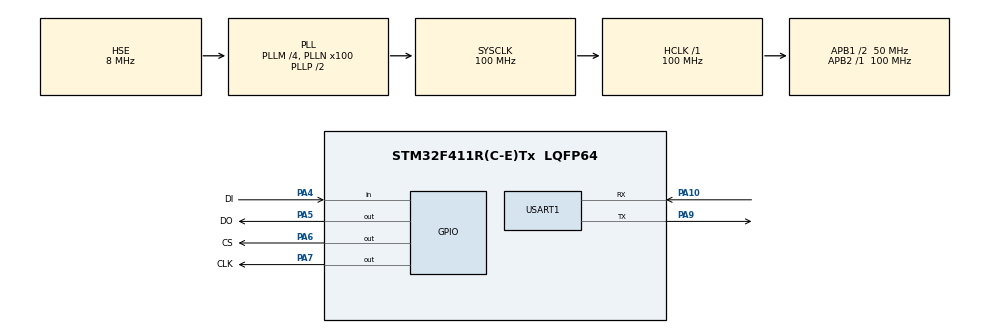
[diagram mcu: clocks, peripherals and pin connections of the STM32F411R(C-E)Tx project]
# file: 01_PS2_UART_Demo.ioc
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Mcu.Family=STM32F4
Mcu.Name=STM32F411R(C-E)Tx
Mcu.Package=LQFP64
NVIC.PriorityGroup=NVIC_PRIORITYGROUP_4
PA10.Mode=Asynchronous
PA10.Signal=USART1_RX
PA13.Mode=Serial_Wire
PA13.Signal=SYS_JTMS-SWDIO
PA14.Mode=Serial_Wire
PA14.Signal=SYS_JTCK-SWCLK
PA4.GPIO_Label=DI
PA4.GPIO_PuPd=GPIO_PULLUP
PA4.Signal=GPIO_Input
PA5.GPIO_Label=DO
PA5.GPIO_Speed=GPIO_SPEED_FREQ_HIGH
PA5.PinState=GPIO_PIN_SET
PA5.Signal=GPIO_Output
PA6.GPIO_Label=CS
PA6.GPIO_Speed=GPIO_SPEED_FREQ_HIGH
PA6.PinState=GPIO_PIN_SET
PA6.Signal=GPIO_Output
PA7.GPIO_Label=CLK
PA7.GPIO_Speed=GPIO_SPEED_FREQ_HIGH
PA7.PinState=GPIO_PIN_SET
PA7.Signal=GPIO_Output
PA9.Mode=Asynchronous
PA9.Signal=USART1_TX
PH0\ -\ OSC_IN.Mode=HSE-External-Oscillator
PH0\ -\ OSC_IN.Signal=RCC_OSC_IN
PH1\ -\ OSC_OUT.Mode=HSE-External-Oscillator
PH1\ -\ OSC_OUT.Signal=RCC_OSC_OUT
ProjectManager.HeapSize=0x200
ProjectManager.StackSize=0x400
ProjectManager.TargetToolchain=MDK-ARM V5
RCC.48MHZClocksFreq_Value=50000000
RCC.AHBFreq_Value=100000000
RCC.APB1CLKDivider=RCC_HCLK_DIV2
RCC.APB1Freq_Value=50000000
RCC.APB1TimFreq_Value=100000000
RCC.APB2Freq_Value=100000000
RCC.APB2TimFreq_Value=100000000
RCC.CortexFreq_Value=100000000
RCC.HCLKFreq_Value=100000000
RCC.HSE_VALUE=8000000
RCC.HSI_VALUE=16000000
RCC.LSE_VALUE=32768
RCC.PLLM=4
RCC.PLLN=100
RCC.PLLSourceVirtual=RCC_PLLSOURCE_HSE
RCC.SYSCLKFreq_VALUE=100000000
RCC.SYSCLKSource=RCC_SYSCLKSOURCE_PLLCLK
RCC.VCOOutputFreq_Value=200000000
USART1.VirtualMode=VM_ASYNC
board=custom

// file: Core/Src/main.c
/* USER CODE BEGIN Header */
/**
  ******************************************************************************
  * @file           : main.c
  * @brief          : Main program body
  ******************************************************************************
  * @attention
  *
  * Copyright (c) 2026 STMicroelectronics.
  * All rights reserved.
  *
  * This software is licensed under terms that can be found in the LICENSE file
  * in the root directory of this software component.
  * If no LICENSE file comes with this software, it is provided AS-IS.
  *
  ******************************************************************************
  */
/* USER CODE END Header */
#include "main.h"
#include "usart.h"
#include "gpio.h"

/* USER CODE BEGIN Includes */
#include "ax_delay.h"   // 软件延时
#include "ax_ps2.h"     // PS2手柄
#include "ax_uart1.h"   // 串口打印
#include <stdio.h>      //
/* USER CODE END Includes */

/* USER CODE BEGIN PTD */
JOYSTICK_TypeDef my_joystick; // 手柄键值结构体
/* USER CODE END PTD */

void SystemClock_Config(void);

int main(void)
{

  /* MCU Configuration--------------------------------------------------------*/

  /* Reset of all peripherals, Initializes the Flash interface and the Systick. */
  HAL_Init();

  /* Configure the system clock */
  SystemClock_Config();

  /* Initialize all configured peripherals */
  MX_GPIO_Init();
  MX_USART1_UART_Init();
  /* USER CODE BEGIN 2 */
	AX_DELAY_Init();// 延时函数初始化
	AX_PS2_Init();// ps2手柄引脚电平初始化
	printf("\r\n  PS2无线手柄HAL库例程  \r\n");
  /* USER CODE END 2 */

  /* Infinite loop */
  /* USER CODE BEGIN WHILE */
  while (1)
  {
		AX_PS2_ScanKey(&my_joystick);// 手柄键值扫描
		// 打印手柄键值ֵ
		printf("MODE:%2x BTN1:%2x BTN2:%2x RJOY_LR:%2x RJOY_UD:%2x LJOY_LR:%2x LJOY_UD:%2x\r\n",
            my_joystick.mode, my_joystick.btn1, my_joystick.btn2,
            my_joystick.RJoy_LR, my_joystick.RJoy_UD,
            my_joystick.LJoy_LR, my_joystick.LJoy_UD); //

		AX_Delayms(30); //延时
    /* USER CODE END WHILE */

  }
}

void SystemClock_Config(void)
{
  RCC_OscInitTypeDef RCC_OscInitStruct = {0};
  RCC_ClkInitTypeDef RCC_ClkInitStruct = {0};

  /** Configure the main internal regulator output voltage
  */
  __HAL_RCC_PWR_CLK_ENABLE();
  __HAL_PWR_VOLTAGESCALING_CONFIG(PWR_REGULATOR_VOLTAGE_SCALE1);

  /** Initializes the RCC Oscillators according to the specified parameters
  * in the RCC_OscInitTypeDef structure.
  */
  RCC_OscInitStruct.OscillatorType = RCC_OSCILLATORTYPE_HSE;
  RCC_OscInitStruct.HSEState = RCC_HSE_ON;
  RCC_OscInitStruct.PLL.PLLState = RCC_PLL_ON;
  RCC_OscInitStruct.PLL.PLLSource = RCC_PLLSOURCE_HSE;
  RCC_OscInitStruct.PLL.PLLM = 4;
  RCC_OscInitStruct.PLL.PLLN = 100;
  RCC_OscInitStruct.PLL.PLLP = RCC_PLLP_DIV2;
  RCC_OscInitStruct.PLL.PLLQ = 4;
  if (HAL_RCC_OscConfig(&RCC_OscInitStruct) != HAL_OK)
  {
    Error_Handler();
  }

  /** Initializes the CPU, AHB and APB buses clocks
  */
  RCC_ClkInitStruct.ClockType = RCC_CLOCKTYPE_HCLK|RCC_CLOCKTYPE_SYSCLK
                              |RCC_CLOCKTYPE_PCLK1|RCC_CLOCKTYPE_PCLK2;
  RCC_ClkInitStruct.SYSCLKSource = RCC_SYSCLKSOURCE_PLLCLK;
  RCC_ClkInitStruct.AHBCLKDivider = RCC_SYSCLK_DIV1;
  RCC_ClkInitStruct.APB1CLKDivider = RCC_HCLK_DIV2;
  RCC_ClkInitStruct.APB2CLKDivider = RCC_HCLK_DIV1;

  if (HAL_RCC_ClockConfig(&RCC_ClkInitStruct, FLASH_LATENCY_3) != HAL_OK)
  {
    Error_Handler();
  }
}

void Error_Handler(void)
{
  __disable_irq();
  while (1)
  {
  }
}
